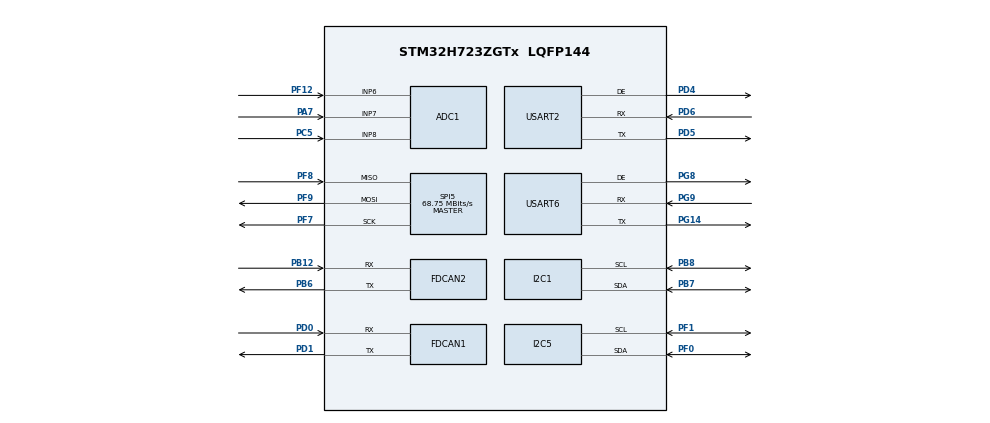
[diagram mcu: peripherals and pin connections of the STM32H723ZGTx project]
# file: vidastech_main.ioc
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ADC1.Channel-0\#ChannelRegularConversion=ADC_CHANNEL_6
ADC1.NbrOfConversionFlag=1
ADC1.OffsetNumber-0\#ChannelRegularConversion=ADC_OFFSET_NONE
ADC1.OffsetSignedSaturation-0\#ChannelRegularConversion=DISABLE
ADC1.Rank-0\#ChannelRegularConversion=1
ADC1.SamplingTime-0\#ChannelRegularConversion=ADC_SAMPLETIME_1CYCLE_5
ADC1.master=1
CORTEX_M7.default_mode_Activation=1
FDCAN1.CalculateBaudRateNominal=2864583
FDCAN1.CalculateTimeBitNominal=349
FDCAN1.CalculateTimeQuantumNominal=116.36363636363636
FDCAN2.CalculateBaudRateNominal=2864583
FDCAN2.CalculateTimeBitNominal=349
FDCAN2.CalculateTimeQuantumNominal=116.36363636363636
FREERTOS.Tasks01=defaultTask,24,128,StartDefaultTask,Default,NULL,Dynamic,NULL,NULL
I2C1.Timing=0x60404E72
I2C5.Timing=0x60404E72
Mcu.Family=STM32H7
Mcu.Name=STM32H723ZGTx
Mcu.Package=LQFP144
NVIC.PriorityGroup=NVIC_PRIORITYGROUP_4
PA0.Signal=S_TIM2_CH1_ETR
PA6.Signal=ADCx_INP3
PA7.Signal=ADCx_INP7
PB0.Signal=S_TIM3_CH3
PB1.Signal=S_TIM3_CH4
PB12.Mode=FDCAN_Activate
PB12.Signal=FDCAN2_RX
PB6.Mode=FDCAN_Activate
PB6.Signal=FDCAN2_TX
PB7.Mode=I2C
PB7.Signal=I2C1_SDA
PB8.Mode=I2C
PB8.Signal=I2C1_SCL
PC14-OSC32_IN.Mode=LSE-External-Oscillator
PC14-OSC32_IN.Signal=RCC_OSC32_IN
PC15-OSC32_OUT.Mode=LSE-External-Oscillator
PC15-OSC32_OUT.Signal=RCC_OSC32_OUT
PC4.Signal=ADCx_INP4
PC5.Signal=ADCx_INP8
PC7.Signal=S_TIM8_CH2
PC8.Signal=S_TIM8_CH3
PC9.Signal=S_TIM8_CH4
PD0.Mode=FDCAN_Activate
PD0.Signal=FDCAN1_RX
PD1.Mode=FDCAN_Activate
PD1.Signal=FDCAN1_TX
PD12.Signal=S_TIM4_CH1
PD4.Mode=Hardware Flow Control (RS485)
PD4.Signal=USART2_DE
PD5.Mode=Asynchronous
PD5.Signal=USART2_TX
PD6.Mode=Asynchronous
PD6.Signal=USART2_RX
PE11.Signal=S_TIM1_CH2
PE13.Signal=S_TIM1_CH3
PE14.Signal=S_TIM1_CH4
PE9.Signal=S_TIM1_CH1
PF0.Mode=I2C
PF0.Signal=I2C5_SDA
PF1.Mode=I2C
PF1.Signal=I2C5_SCL
PF11.Signal=ADC1_INP2
PF12.Mode=IN6-Single-Ended
PF12.Signal=ADC1_INP6
PF7.Mode=Full_Duplex_Master
PF7.Signal=SPI5_SCK
PF8.Mode=Full_Duplex_Master
PF8.Signal=SPI5_MISO
PF9.Mode=Full_Duplex_Master
PF9.Signal=SPI5_MOSI
PG14.Mode=Asynchronous
PG14.Signal=USART6_TX
PG8.Mode=Hardware Flow Control (RS485)
PG8.Signal=USART6_DE
PG9.Mode=Asynchronous
PG9.Signal=USART6_RX
PH0-OSC_IN.Mode=HSE-External-Oscillator
PH0-OSC_IN.Signal=RCC_OSC_IN
PH1-OSC_OUT.Mode=HSE-External-Oscillator
PH1-OSC_OUT.Signal=RCC_OSC_OUT
ProjectManager.HeapSize=0x200
ProjectManager.StackSize=0x400
ProjectManager.TargetToolchain=CMake
RCC.ADCFreq_Value=100000000
RCC.APB1Freq_Value=137500000
RCC.APB2Freq_Value=137500000
RCC.APB3Freq_Value=137500000
RCC.APB4Freq_Value=137500000
RCC.CortexFreq_Value=550000000
RCC.D1PPRE=RCC_APB3_DIV2
RCC.D2PPRE1=RCC_APB1_DIV2
RCC.D2PPRE2=RCC_APB2_DIV2
RCC.D3PPRE=RCC_APB4_DIV2
RCC.DIVM1=2
RCC.DIVM2=2
RCC.DIVN1=44
RCC.DIVN2=16
RCC.DIVP1=1
RCC.DIVQ1=4
RCC.HCLKFreq_Value=275000000
RCC.HPRE=RCC_HCLK_DIV2
RCC.PLL2FRACN=0
RCC.PLL3FRACN=0
RCC.PLLFRACN=0
RCC.PLLSourceVirtual=RCC_PLLSOURCE_HSE
RCC.SYSCLKFreq_VALUE=550000000
RCC.SYSCLKSource=RCC_SYSCLKSOURCE_PLLCLK
RCC.USBFreq_Value=137500000
SH.ADCx_INP3.0=ADC1_INP3
SH.ADCx_INP4.0=ADC1_INP4
SH.ADCx_INP7.0=ADC1_INP7,IN7-Single-Ended
SH.ADCx_INP8.0=ADC1_INP8,IN8-Single-Ended
SH.S_TIM1_CH1.0=TIM1_CH1
SH.S_TIM1_CH2.0=TIM1_CH2
SH.S_TIM1_CH3.0=TIM1_CH3
SH.S_TIM1_CH4.0=TIM1_CH4
SH.S_TIM2_CH1_ETR.0=TIM2_CH1
SH.S_TIM3_CH3.0=TIM3_CH3
SH.S_TIM3_CH4.0=TIM3_CH4
SH.S_TIM4_CH1.0=TIM4_CH1
SH.S_TIM8_CH2.0=TIM8_CH2
SH.S_TIM8_CH3.0=TIM8_CH3
SH.S_TIM8_CH4.0=TIM8_CH4
SPI5.CalculateBaudRate=68.75 MBits/s
SPI5.Direction=SPI_DIRECTION_2LINES
SPI5.Mode=SPI_MODE_MASTER
SPI5.VirtualType=VM_MASTER
USART2.VirtualMode-Asynchronous=VM_ASYNC
USART2.VirtualMode-Hardware\ Flow\ Control\ (RS485)=VM_ASYNC
USART6.VirtualMode-Asynchronous=VM_ASYNC
USART6.VirtualMode-Hardware\ Flow\ Control\ (RS485)=VM_ASYNC
VP_FREERTOS_VS_CMSIS_V2.Mode=CMSIS_V2
VP_MEMORYMAP_VS_MEMORYMAP.Mode=CurAppReg
board=custom

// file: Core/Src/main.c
/* USER CODE BEGIN Header */
/**
  ******************************************************************************
  * @file           : main.c
  * @brief          : Main program body
  ******************************************************************************
  * @attention
  *
  * Copyright (c) 2025 STMicroelectronics.
  * All rights reserved.
  *
  * This software is licensed under terms that can be found in the LICENSE file
  * in the root directory of this software component.
  * If no LICENSE file comes with this software, it is provided AS-IS.
  *
  ******************************************************************************
  */
/* USER CODE END Header */
#include "main.h"
#include "cmsis_os.h"

/* USER CODE BEGIN Includes */
#include "ssd1306_thread.h"

/* USER CODE END Includes */

ADC_HandleTypeDef hadc1;

FDCAN_HandleTypeDef hfdcan1;
FDCAN_HandleTypeDef hfdcan2;

I2C_HandleTypeDef hi2c1;
I2C_HandleTypeDef hi2c5;

SPI_HandleTypeDef hspi5;

UART_HandleTypeDef huart2;
UART_HandleTypeDef huart6;

/* Definitions for defaultTask */
osThreadId_t defaultTaskHandle;
const osThreadAttr_t defaultTask_attributes = {
  .name = "defaultTask",
  .stack_size = 128 * 4,
  .priority = (osPriority_t) osPriorityNormal,
};

void SystemClock_Config(void);
static void MPU_Config(void);
static void MX_GPIO_Init(void);
static void MX_FDCAN1_Init(void);
static void MX_FDCAN2_Init(void);
static void MX_I2C5_Init(void);
static void MX_USART2_UART_Init(void);
static void MX_USART6_UART_Init(void);
static void MX_ADC1_Init(void);
static void MX_I2C1_Init(void);
static void MX_SPI5_Init(void);
void StartDefaultTask(void *argument);

int main(void)
{

  /* MPU Configuration--------------------------------------------------------*/
  MPU_Config();

  /* MCU Configuration--------------------------------------------------------*/

  /* Reset of all peripherals, Initializes the Flash interface and the Systick. */
  HAL_Init();

  /* Configure the system clock */
  SystemClock_Config();

  /* Initialize all configured peripherals */
  MX_GPIO_Init();
  MX_FDCAN1_Init();
  MX_FDCAN2_Init();
  MX_I2C5_Init();
  MX_USART2_UART_Init();
  MX_USART6_UART_Init();
  MX_ADC1_Init();
  MX_I2C1_Init();
  MX_SPI5_Init();

  /* Init scheduler */
  osKernelInitialize();

  /* Create the thread(s) */
  /* creation of defaultTask */
  defaultTaskHandle = osThreadNew(StartDefaultTask, NULL, &defaultTask_attributes);

  /* Start scheduler */
  osKernelStart();

  /* We should never get here as control is now taken by the scheduler */

  /* Infinite loop */
  while (1)
  {

  }
}

void SystemClock_Config(void)
{
  RCC_OscInitTypeDef RCC_OscInitStruct = {0};
  RCC_ClkInitTypeDef RCC_ClkInitStruct = {0};

  /** Supply configuration update enable
  */
  HAL_PWREx_ConfigSupply(PWR_LDO_SUPPLY);

  /** Configure the main internal regulator output voltage
  */
  __HAL_PWR_VOLTAGESCALING_CONFIG(PWR_REGULATOR_VOLTAGE_SCALE0);

  while(!__HAL_PWR_GET_FLAG(PWR_FLAG_VOSRDY)) {}

  /** Initializes the RCC Oscillators according to the specified parameters
  * in the RCC_OscInitTypeDef structure.
  */
  RCC_OscInitStruct.OscillatorType = RCC_OSCILLATORTYPE_HSE;
  RCC_OscInitStruct.HSEState = RCC_HSE_ON;
  RCC_OscInitStruct.PLL.PLLState = RCC_PLL_ON;
  RCC_OscInitStruct.PLL.PLLSource = RCC_PLLSOURCE_HSE;
  RCC_OscInitStruct.PLL.PLLM = 2;
  RCC_OscInitStruct.PLL.PLLN = 44;
  RCC_OscInitStruct.PLL.PLLP = 1;
  RCC_OscInitStruct.PLL.PLLQ = 4;
  RCC_OscInitStruct.PLL.PLLR = 2;
  RCC_OscInitStruct.PLL.PLLRGE = RCC_PLL1VCIRANGE_3;
  RCC_OscInitStruct.PLL.PLLVCOSEL = RCC_PLL1VCOWIDE;
  RCC_OscInitStruct.PLL.PLLFRACN = 0;
  if (HAL_RCC_OscConfig(&RCC_OscInitStruct) != HAL_OK)
  {
    Error_Handler();
  }

  /** Initializes the CPU, AHB and APB buses clocks
  */
  RCC_ClkInitStruct.ClockType = RCC_CLOCKTYPE_HCLK|RCC_CLOCKTYPE_SYSCLK
                              |RCC_CLOCKTYPE_PCLK1|RCC_CLOCKTYPE_PCLK2
                              |RCC_CLOCKTYPE_D3PCLK1|RCC_CLOCKTYPE_D1PCLK1;
  RCC_ClkInitStruct.SYSCLKSource = RCC_SYSCLKSOURCE_PLLCLK;
  RCC_ClkInitStruct.SYSCLKDivider = RCC_SYSCLK_DIV1;
  RCC_ClkInitStruct.AHBCLKDivider = RCC_HCLK_DIV2;
  RCC_ClkInitStruct.APB3CLKDivider = RCC_APB3_DIV2;
  RCC_ClkInitStruct.APB1CLKDivider = RCC_APB1_DIV2;
  RCC_ClkInitStruct.APB2CLKDivider = RCC_APB2_DIV2;
  RCC_ClkInitStruct.APB4CLKDivider = RCC_APB4_DIV2;

  if (HAL_RCC_ClockConfig(&RCC_ClkInitStruct, FLASH_LATENCY_3) != HAL_OK)
  {
    Error_Handler();
  }
}

static void MX_ADC1_Init(void)
{

  ADC_MultiModeTypeDef multimode = {0};
  ADC_ChannelConfTypeDef sConfig = {0};

  /** Common config
  */
  hadc1.Instance = ADC1;
  hadc1.Init.ClockPrescaler = ADC_CLOCK_ASYNC_DIV1;
  hadc1.Init.Resolution = ADC_RESOLUTION_16B;
  hadc1.Init.ScanConvMode = ADC_SCAN_DISABLE;
  hadc1.Init.EOCSelection = ADC_EOC_SINGLE_CONV;
  hadc1.Init.LowPowerAutoWait = DISABLE;
  hadc1.Init.ContinuousConvMode = DISABLE;
  hadc1.Init.NbrOfConversion = 1;
  hadc1.Init.DiscontinuousConvMode = DISABLE;
  hadc1.Init.ExternalTrigConv = ADC_SOFTWARE_START;
  hadc1.Init.ExternalTrigConvEdge = ADC_EXTERNALTRIGCONVEDGE_NONE;
  hadc1.Init.ConversionDataManagement = ADC_CONVERSIONDATA_DR;
  hadc1.Init.Overrun = ADC_OVR_DATA_PRESERVED;
  hadc1.Init.LeftBitShift = ADC_LEFTBITSHIFT_NONE;
  hadc1.Init.OversamplingMode = DISABLE;
  hadc1.Init.Oversampling.Ratio = 1;
  if (HAL_ADC_Init(&hadc1) != HAL_OK)
  {
    Error_Handler();
  }

  /** Configure the ADC multi-mode
  */
  multimode.Mode = ADC_MODE_INDEPENDENT;
  if (HAL_ADCEx_MultiModeConfigChannel(&hadc1, &multimode) != HAL_OK)
  {
    Error_Handler();
  }

  /** Configure Regular Channel
  */
  sConfig.Channel = ADC_CHANNEL_6;
  sConfig.Rank = ADC_REGULAR_RANK_1;
  sConfig.SamplingTime = ADC_SAMPLETIME_1CYCLE_5;
  sConfig.SingleDiff = ADC_SINGLE_ENDED;
  sConfig.OffsetNumber = ADC_OFFSET_NONE;
  sConfig.Offset = 0;
  sConfig.OffsetSignedSaturation = DISABLE;
  if (HAL_ADC_ConfigChannel(&hadc1, &sConfig) != HAL_OK)
  {
    Error_Handler();
  }

}

static void MX_FDCAN1_Init(void)
{

  hfdcan1.Instance = FDCAN1;
  hfdcan1.Init.FrameFormat = FDCAN_FRAME_CLASSIC;
  hfdcan1.Init.Mode = FDCAN_MODE_NORMAL;
  hfdcan1.Init.AutoRetransmission = DISABLE;
  hfdcan1.Init.TransmitPause = DISABLE;
  hfdcan1.Init.ProtocolException = DISABLE;
  hfdcan1.Init.NominalPrescaler = 16;
  hfdcan1.Init.NominalSyncJumpWidth = 1;
  hfdcan1.Init.NominalTimeSeg1 = 1;
  hfdcan1.Init.NominalTimeSeg2 = 1;
  hfdcan1.Init.DataPrescaler = 1;
  hfdcan1.Init.DataSyncJumpWidth = 1;
  hfdcan1.Init.DataTimeSeg1 = 1;
  hfdcan1.Init.DataTimeSeg2 = 1;
  hfdcan1.Init.MessageRAMOffset = 0;
  hfdcan1.Init.StdFiltersNbr = 0;
  hfdcan1.Init.ExtFiltersNbr = 0;
  hfdcan1.Init.RxFifo0ElmtsNbr = 0;
  hfdcan1.Init.RxFifo0ElmtSize = FDCAN_DATA_BYTES_8;
  hfdcan1.Init.RxFifo1ElmtsNbr = 0;
  hfdcan1.Init.RxFifo1ElmtSize = FDCAN_DATA_BYTES_8;
  hfdcan1.Init.RxBuffersNbr = 0;
  hfdcan1.Init.RxBufferSize = FDCAN_DATA_BYTES_8;
  hfdcan1.Init.TxEventsNbr = 0;
  hfdcan1.Init.TxBuffersNbr = 0;
  hfdcan1.Init.TxFifoQueueElmtsNbr = 0;
  hfdcan1.Init.TxFifoQueueMode = FDCAN_TX_FIFO_OPERATION;
  hfdcan1.Init.TxElmtSize = FDCAN_DATA_BYTES_8;
  if (HAL_FDCAN_Init(&hfdcan1) != HAL_OK)
  {
    Error_Handler();
  }

}

static void MX_FDCAN2_Init(void)
{

  hfdcan2.Instance = FDCAN2;
  hfdcan2.Init.FrameFormat = FDCAN_FRAME_CLASSIC;
  hfdcan2.Init.Mode = FDCAN_MODE_NORMAL;
  hfdcan2.Init.AutoRetransmission = DISABLE;
  hfdcan2.Init.TransmitPause = DISABLE;
  hfdcan2.Init.ProtocolException = DISABLE;
  hfdcan2.Init.NominalPrescaler = 16;
  hfdcan2.Init.NominalSyncJumpWidth = 1;
  hfdcan2.Init.NominalTimeSeg1 = 1;
  hfdcan2.Init.NominalTimeSeg2 = 1;
  hfdcan2.Init.DataPrescaler = 1;
  hfdcan2.Init.DataSyncJumpWidth = 1;
  hfdcan2.Init.DataTimeSeg1 = 1;
  hfdcan2.Init.DataTimeSeg2 = 1;
  hfdcan2.Init.MessageRAMOffset = 0;
  hfdcan2.Init.StdFiltersNbr = 0;
  hfdcan2.Init.ExtFiltersNbr = 0;
  hfdcan2.Init.RxFifo0ElmtsNbr = 0;
  hfdcan2.Init.RxFifo0ElmtSize = FDCAN_DATA_BYTES_8;
  hfdcan2.Init.RxFifo1ElmtsNbr = 0;
  hfdcan2.Init.RxFifo1ElmtSize = FDCAN_DATA_BYTES_8;
  hfdcan2.Init.RxBuffersNbr = 0;
  hfdcan2.Init.RxBufferSize = FDCAN_DATA_BYTES_8;
  hfdcan2.Init.TxEventsNbr = 0;
  hfdcan2.Init.TxBuffersNbr = 0;
  hfdcan2.Init.TxFifoQueueElmtsNbr = 0;
  hfdcan2.Init.TxFifoQueueMode = FDCAN_TX_FIFO_OPERATION;
  hfdcan2.Init.TxElmtSize = FDCAN_DATA_BYTES_8;
  if (HAL_FDCAN_Init(&hfdcan2) != HAL_OK)
  {
    Error_Handler();
  }

}

static void MX_I2C1_Init(void)
{

  hi2c1.Instance = I2C1;
  hi2c1.Init.Timing = 0x60404E72;
  hi2c1.Init.OwnAddress1 = 0;
  hi2c1.Init.AddressingMode = I2C_ADDRESSINGMODE_7BIT;
  hi2c1.Init.DualAddressMode = I2C_DUALADDRESS_DISABLE;
  hi2c1.Init.OwnAddress2 = 0;
  hi2c1.Init.OwnAddress2Masks = I2C_OA2_NOMASK;
  hi2c1.Init.GeneralCallMode = I2C_GENERALCALL_DISABLE;
  hi2c1.Init.NoStretchMode = I2C_NOSTRETCH_DISABLE;
  if (HAL_I2C_Init(&hi2c1) != HAL_OK)
  {
    Error_Handler();
  }

  /** Configure Analogue filter
  */
  if (HAL_I2CEx_ConfigAnalogFilter(&hi2c1, I2C_ANALOGFILTER_ENABLE) != HAL_OK)
  {
    Error_Handler();
  }

  /** Configure Digital filter
  */
  if (HAL_I2CEx_ConfigDigitalFilter(&hi2c1, 0) != HAL_OK)
  {
    Error_Handler();
  }

}

static void MX_I2C5_Init(void)
{

  hi2c5.Instance = I2C5;
  hi2c5.Init.Timing = 0x60404E72;
  hi2c5.Init.OwnAddress1 = 0;
  hi2c5.Init.AddressingMode = I2C_ADDRESSINGMODE_7BIT;
  hi2c5.Init.DualAddressMode = I2C_DUALADDRESS_DISABLE;
  hi2c5.Init.OwnAddress2 = 0;
  hi2c5.Init.OwnAddress2Masks = I2C_OA2_NOMASK;
  hi2c5.Init.GeneralCallMode = I2C_GENERALCALL_DISABLE;
  hi2c5.Init.NoStretchMode = I2C_NOSTRETCH_DISABLE;
  if (HAL_I2C_Init(&hi2c5) != HAL_OK)
  {
    Error_Handler();
  }

  /** Configure Analogue filter
  */
  if (HAL_I2CEx_ConfigAnalogFilter(&hi2c5, I2C_ANALOGFILTER_ENABLE) != HAL_OK)
  {
    Error_Handler();
  }

  /** Configure Digital filter
  */
  if (HAL_I2CEx_ConfigDigitalFilter(&hi2c5, 0) != HAL_OK)
  {
    Error_Handler();
  }

}

static void MX_SPI5_Init(void)
{

  /* SPI5 parameter configuration*/
  hspi5.Instance = SPI5;
  hspi5.Init.Mode = SPI_MODE_MASTER;
  hspi5.Init.Direction = SPI_DIRECTION_2LINES;
  hspi5.Init.DataSize = SPI_DATASIZE_4BIT;
  hspi5.Init.CLKPolarity = SPI_POLARITY_LOW;
  hspi5.Init.CLKPhase = SPI_PHASE_1EDGE;
  hspi5.Init.NSS = SPI_NSS_SOFT;
  hspi5.Init.BaudRatePrescaler = SPI_BAUDRATEPRESCALER_2;
  hspi5.Init.FirstBit = SPI_FIRSTBIT_MSB;
  hspi5.Init.TIMode = SPI_TIMODE_DISABLE;
  hspi5.Init.CRCCalculation = SPI_CRCCALCULATION_DISABLE;
  hspi5.Init.CRCPolynomial = 0x0;
  hspi5.Init.NSSPMode = SPI_NSS_PULSE_ENABLE;
  hspi5.Init.NSSPolarity = SPI_NSS_POLARITY_LOW;
  hspi5.Init.FifoThreshold = SPI_FIFO_THRESHOLD_01DATA;
  hspi5.Init.TxCRCInitializationPattern = SPI_CRC_INITIALIZATION_ALL_ZERO_PATTERN;
  hspi5.Init.RxCRCInitializationPattern = SPI_CRC_INITIALIZATION_ALL_ZERO_PATTERN;
  hspi5.Init.MasterSSIdleness = SPI_MASTER_SS_IDLENESS_00CYCLE;
  hspi5.Init.MasterInterDataIdleness = SPI_MASTER_INTERDATA_IDLENESS_00CYCLE;
  hspi5.Init.MasterReceiverAutoSusp = SPI_MASTER_RX_AUTOSUSP_DISABLE;
  hspi5.Init.MasterKeepIOState = SPI_MASTER_KEEP_IO_STATE_DISABLE;
  hspi5.Init.IOSwap = SPI_IO_SWAP_DISABLE;
  if (HAL_SPI_Init(&hspi5) != HAL_OK)
  {
    Error_Handler();
  }

}

static void MX_USART2_UART_Init(void)
{

  huart2.Instance = USART2;
  huart2.Init.BaudRate = 115200;
  huart2.Init.WordLength = UART_WORDLENGTH_8B;
  huart2.Init.StopBits = UART_STOPBITS_1;
  huart2.Init.Parity = UART_PARITY_NONE;
  huart2.Init.Mode = UART_MODE_TX_RX;
  huart2.Init.HwFlowCtl = UART_HWCONTROL_NONE;
  huart2.Init.OverSampling = UART_OVERSAMPLING_16;
  huart2.Init.OneBitSampling = UART_ONE_BIT_SAMPLE_DISABLE;
  huart2.Init.ClockPrescaler = UART_PRESCALER_DIV1;
  huart2.AdvancedInit.AdvFeatureInit = UART_ADVFEATURE_NO_INIT;
  if (HAL_RS485Ex_Init(&huart2, UART_DE_POLARITY_HIGH, 0, 0) != HAL_OK)
  {
    Error_Handler();
  }
  if (HAL_UARTEx_SetTxFifoThreshold(&huart2, UART_TXFIFO_THRESHOLD_1_8) != HAL_OK)
  {
    Error_Handler();
  }
  if (HAL_UARTEx_SetRxFifoThreshold(&huart2, UART_RXFIFO_THRESHOLD_1_8) != HAL_OK)
  {
    Error_Handler();
  }
  if (HAL_UARTEx_DisableFifoMode(&huart2) != HAL_OK)
  {
    Error_Handler();
  }

}

static void MX_USART6_UART_Init(void)
{

  huart6.Instance = USART6;
  huart6.Init.BaudRate = 115200;
  huart6.Init.WordLength = UART_WORDLENGTH_8B;
  huart6.Init.StopBits = UART_STOPBITS_1;
  huart6.Init.Parity = UART_PARITY_NONE;
  huart6.Init.Mode = UART_MODE_TX_RX;
  huart6.Init.HwFlowCtl = UART_HWCONTROL_NONE;
  huart6.Init.OverSampling = UART_OVERSAMPLING_16;
  huart6.Init.OneBitSampling = UART_ONE_BIT_SAMPLE_DISABLE;
  huart6.Init.ClockPrescaler = UART_PRESCALER_DIV1;
  huart6.AdvancedInit.AdvFeatureInit = UART_ADVFEATURE_NO_INIT;
  if (HAL_RS485Ex_Init(&huart6, UART_DE_POLARITY_HIGH, 0, 0) != HAL_OK)
  {
    Error_Handler();
  }
  if (HAL_UARTEx_SetTxFifoThreshold(&huart6, UART_TXFIFO_THRESHOLD_1_8) != HAL_OK)
  {
    Error_Handler();
  }
  if (HAL_UARTEx_SetRxFifoThreshold(&huart6, UART_RXFIFO_THRESHOLD_1_8) != HAL_OK)
  {
    Error_Handler();
  }
  if (HAL_UARTEx_DisableFifoMode(&huart6) != HAL_OK)
  {
    Error_Handler();
  }

}

static void MX_GPIO_Init(void)
{
  GPIO_InitTypeDef GPIO_InitStruct = {0};

  /* GPIO Ports Clock Enable */
  __HAL_RCC_GPIOC_CLK_ENABLE();
  __HAL_RCC_GPIOF_CLK_ENABLE();
  __HAL_RCC_GPIOH_CLK_ENABLE();
  __HAL_RCC_GPIOA_CLK_ENABLE();
  __HAL_RCC_GPIOB_CLK_ENABLE();
  __HAL_RCC_GPIOE_CLK_ENABLE();
  __HAL_RCC_GPIOD_CLK_ENABLE();
  __HAL_RCC_GPIOG_CLK_ENABLE();

  /*Configure GPIO pin : PA0 */
  GPIO_InitStruct.Pin = GPIO_PIN_0;
  GPIO_InitStruct.Mode = GPIO_MODE_AF_PP;
  GPIO_InitStruct.Pull = GPIO_NOPULL;
  GPIO_InitStruct.Speed = GPIO_SPEED_FREQ_LOW;
  GPIO_InitStruct.Alternate = GPIO_AF1_TIM2;
  HAL_GPIO_Init(GPIOA, &GPIO_InitStruct);

  /*Configure GPIO pins : PB0 PB1 */
  GPIO_InitStruct.Pin = GPIO_PIN_0|GPIO_PIN_1;
  GPIO_InitStruct.Mode = GPIO_MODE_AF_PP;
  GPIO_InitStruct.Pull = GPIO_NOPULL;
  GPIO_InitStruct.Speed = GPIO_SPEED_FREQ_LOW;
  GPIO_InitStruct.Alternate = GPIO_AF2_TIM3;
  HAL_GPIO_Init(GPIOB, &GPIO_InitStruct);

  /*Configure GPIO pins : PE9 PE11 PE13 PE14 */
  GPIO_InitStruct.Pin = GPIO_PIN_9|GPIO_PIN_11|GPIO_PIN_13|GPIO_PIN_14;
  GPIO_InitStruct.Mode = GPIO_MODE_AF_PP;
  GPIO_InitStruct.Pull = GPIO_NOPULL;
  GPIO_InitStruct.Speed = GPIO_SPEED_FREQ_LOW;
  GPIO_InitStruct.Alternate = GPIO_AF1_TIM1;
  HAL_GPIO_Init(GPIOE, &GPIO_InitStruct);

  /*Configure GPIO pin : PD12 */
  GPIO_InitStruct.Pin = GPIO_PIN_12;
  GPIO_InitStruct.Mode = GPIO_MODE_AF_PP;
  GPIO_InitStruct.Pull = GPIO_NOPULL;
  GPIO_InitStruct.Speed = GPIO_SPEED_FREQ_LOW;
  GPIO_InitStruct.Alternate = GPIO_AF2_TIM4;
  HAL_GPIO_Init(GPIOD, &GPIO_InitStruct);

  /*Configure GPIO pins : PC7 PC8 PC9 */
  GPIO_InitStruct.Pin = GPIO_PIN_7|GPIO_PIN_8|GPIO_PIN_9;
  GPIO_InitStruct.Mode = GPIO_MODE_AF_PP;
  GPIO_InitStruct.Pull = GPIO_NOPULL;
  GPIO_InitStruct.Speed = GPIO_SPEED_FREQ_LOW;
  GPIO_InitStruct.Alternate = GPIO_AF3_TIM8;
  HAL_GPIO_Init(GPIOC, &GPIO_InitStruct);

}

void StartDefaultTask(void *argument)
{
  for(;;)
  {
    osDelay(1);
  }
}

 /* MPU Configuration */

void MPU_Config(void)
{
  MPU_Region_InitTypeDef MPU_InitStruct = {0};

  /* Disables the MPU */
  HAL_MPU_Disable();

  /** Initializes and configures the Region and the memory to be protected
  */
  MPU_InitStruct.Enable = MPU_REGION_ENABLE;
  MPU_InitStruct.Number = MPU_REGION_NUMBER0;
  MPU_InitStruct.BaseAddress = 0x0;
  MPU_InitStruct.Size = MPU_REGION_SIZE_4GB;
  MPU_InitStruct.SubRegionDisable = 0x87;
  MPU_InitStruct.TypeExtField = MPU_TEX_LEVEL0;
  MPU_InitStruct.AccessPermission = MPU_REGION_NO_ACCESS;
  MPU_InitStruct.DisableExec = MPU_INSTRUCTION_ACCESS_DISABLE;
  MPU_InitStruct.IsShareable = MPU_ACCESS_SHAREABLE;
  MPU_InitStruct.IsCacheable = MPU_ACCESS_NOT_CACHEABLE;
  MPU_InitStruct.IsBufferable = MPU_ACCESS_NOT_BUFFERABLE;

  HAL_MPU_ConfigRegion(&MPU_InitStruct);
  /* Enables the MPU */
  HAL_MPU_Enable(MPU_PRIVILEGED_DEFAULT);

}

void Error_Handler(void)
{
  __disable_irq();
  while (1)
  {
  }
}
